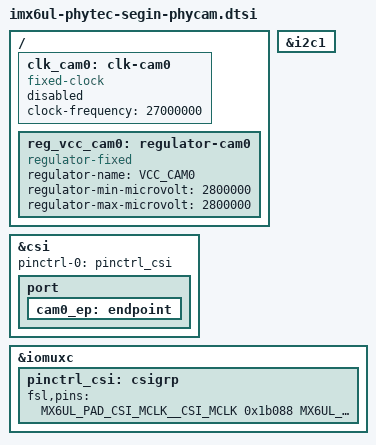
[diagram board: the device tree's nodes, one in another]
// SPDX-License-Identifier: (GPL-2.0+ OR MIT)
/*
 * Copyright (C) 2021 PHYTEC Messtechnik GmbH
 * Author: Stefan Riedmueller <s.riedmueller@phytec.de>
 */

/ {
	clk_cam0: clk-cam0 {
		#clock-cells = <0>;

		compatible = "fixed-clock";
		clock-frequency = <27000000>;
		status = "disabled";
	};

	reg_vcc_cam0: regulator-cam0 {
		compatible = "regulator-fixed";
		regulator-name = "VCC_CAM0";
		regulator-min-microvolt = <2800000>;
		regulator-max-microvolt = <2800000>;
	};
};

cam0_i2c: &i2c1 {};

&csi {
	pinctrl-names = "default";
	pinctrl-0 = <&pinctrl_csi>;

	port {
		cam0_ep: endpoint {};
	};
};

&iomuxc {
	pinctrl_csi: csigrp {
		fsl,pins = <
			MX6UL_PAD_CSI_MCLK__CSI_MCLK		0x1b088
			MX6UL_PAD_CSI_PIXCLK__CSI_PIXCLK	0x1b088
			MX6UL_PAD_CSI_VSYNC__CSI_VSYNC		0x1b088
			MX6UL_PAD_CSI_HSYNC__CSI_HSYNC		0x1b088
			MX6UL_PAD_CSI_DATA00__CSI_DATA02	0x1b088
			MX6UL_PAD_CSI_DATA01__CSI_DATA03	0x1b088
			MX6UL_PAD_CSI_DATA02__CSI_DATA04	0x1b088
			MX6UL_PAD_CSI_DATA03__CSI_DATA05	0x1b088
			MX6UL_PAD_CSI_DATA04__CSI_DATA06	0x1b088
			MX6UL_PAD_CSI_DATA05__CSI_DATA07	0x1b088
			MX6UL_PAD_CSI_DATA06__CSI_DATA08	0x1b088
			MX6UL_PAD_CSI_DATA07__CSI_DATA09	0x1b088
		>;
	};
};
